# CY8C5888LTI_LP097 register map
File version: 0.1
CY8C58LP
Registers are 8-bit, read-write, no defined reset value unless marked. A register's access mark holds for its fields unless they carry their own. Offsets are from the block's base; lines under a group give offsets from that group; [hi:lo] are bit positions; {n}, {i} and the like mark numbered series; 'fields as' and 'values as' point back to an identical list; <NAME> marks a mode.

## Memory map
0x00000000 SPIS
0x00000000 UART_1 — UART

## SPIS
Base 0x00000000
0x4000640B SPIS_TX_DATA
0x4000640B SPIS_RX_DATA
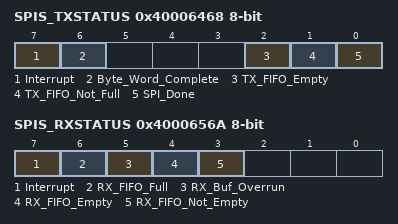
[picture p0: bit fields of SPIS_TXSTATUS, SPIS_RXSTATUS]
0x40006468 SPIS_TXSTATUS
  [7] Interrupt ro — Set when interrupt occurs
  [6] Byte_Word_Complete ro — Set when a byte/word transmit has completed
  [2] TX_FIFO_Empty ro — Set when the TX Data FIFO is empty
  [1] TX_FIFO_Not_Full ro — Set when the TX Data FIFO is not full
  [0] SPI_Done ro — Set when all of the data in the transmit FIFO has been sent. Set when Byte/Word Complete has been set and TX Data FIFO is empty
0x4000656A SPIS_RXSTATUS
  [7] Interrupt ro — Set when interrupt occurs
  [6] RX_FIFO_Full ro — Set when the RX Data FIFO is full
  [5] RX_Buf_Overrun ro — Set when RX Data has overrun the 4 byte/word FIFO without being moved to the RX buffer cmemory array (if one exists)
  [4] RX_FIFO_Empty ro — Set when the RX Data FIFO is empty
  [3] RX_FIFO_Not_Empty ro — Set when the RX Data FIFO is not empty. That is, at least one byte/word is in the RX FIFO

## UART_1 — UART
Base 0x00000000
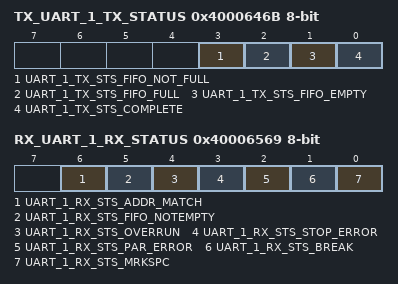
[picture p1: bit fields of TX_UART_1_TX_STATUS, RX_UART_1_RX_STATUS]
0x4000646B TX_UART_1_TX_STATUS — TX status register
  [3] UART_1_TX_STS_FIFO_NOT_FULL ro, [2] UART_1_TX_STS_FIFO_FULL ro, [1] UART_1_TX_STS_FIFO_EMPTY ro, [0] UART_1_TX_STS_COMPLETE ro
0x40006529 RX_UART_1_RX_ADDRESS1 — RX Address1 Register
0x40006539 RX_UART_1_RX_ADDRESS2 — RX Address2 Register
0x40006548 TX_UART_1_TX_DATA — TX Data Register
0x40006549 RX_UART_1_RX_DATA — RX Data Register
0x40006569 RX_UART_1_RX_STATUS — RX status register
  [6] UART_1_RX_STS_ADDR_MATCH ro, [5] UART_1_RX_STS_FIFO_NOTEMPTY ro, [4] UART_1_RX_STS_OVERRUN ro, [3] UART_1_RX_STS_STOP_ERROR ro, [2] UART_1_RX_STS_PAR_ERROR ro, [1] UART_1_RX_STS_BREAK ro, [0] UART_1_RX_STS_MRKSPC ro
